# GD32F30x_XD register map
File version: 1.0
CPU: CM4 r2p1, little endian, MPU, FPU, 4 interrupt priority bits
Registers are 32-bit, read-write, reset 0x0 unless marked. A register's access mark holds for its fields unless they carry their own. Offsets are from the block's base; [hi:lo] are bit positions; {n}, {i} and the like mark numbered series.

## DAC — Digital-to-analog converter
Base 0x40007400
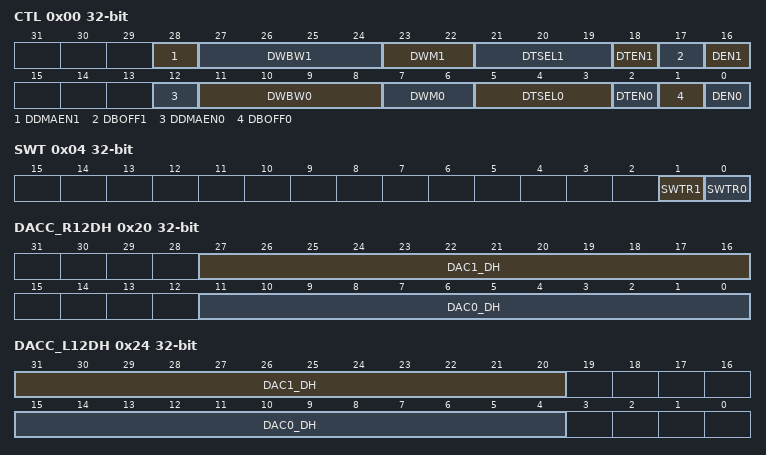
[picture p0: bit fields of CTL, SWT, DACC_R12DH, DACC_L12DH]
0x00 CTL — control register
  [28] DDMAEN1 — DAC1 DMA enable
  [27:24] DWBW1 — DAC1 noise wave bit width
  [23:22] DWM1 — DAC1 noise wave mode
  [21:19] DTSEL1 — DAC1 trigger selection
  [18] DTEN1 — DAC1 trigger enable
  [17] DBOFF1 — DAC1 output buffer turn off
  [16] DEN1 — DAC1 enable
  [12] DDMAEN0 — DAC0 DMA enable
  [11:8] DWBW0 — DAC0 noise wave bit width
  [7:6] DWM0 — DAC0 noise wave mode
  [5:3] DTSEL0 — DAC0 trigger selection
  [2] DTEN0 — DAC0 trigger enable
  [1] DBOFF0 — DAC0 output buffer turn off
  [0] DEN0 — DAC0 enable
0x04 SWT wo — software trigger register
  [1] SWTR1 — DAC1 software trigger
  [0] SWTR0 — DAC0 software trigger
0x08 OUT0_R12DH — DACx_OUT0 12-bit right-aligned data holding register
  [11:0] OUT0_DH — DACx_OUT0 12-bit right-aligned data
0x0C DOUT0_L12DH — DACx_OUT0 12-bit left-aligned data holding register
  [15:4] OUT0_DH — DACx_OUT0 12-bit left-aligned data
0x10 OUT0_R8DH — DACx_OUT0 8-bit right-aligned data holding register
  [7:0] OUT0_DH — DACx_OUT0 8-bit right-aligned data
0x14 OUT1_R12DH — DACx_OUT1 12-bit right-aligned data holding register
  [11:0] OUT1_DH — DACx_OUT1 12-bit right-aligned data
0x18 OUT1_L12DH — DACx_OUT1 12-bit left-aligned data holding register
  [15:4] OUT1_DH — DACx_OUT1 12-bit left-aligned data
0x1C OUT1_R8DH — DACx_OUT1 8-bit right-aligned data holding register (DAC_OUT1_R8DH)
  [7:0] DAC1_DH — DACx_OUT1 8-bit right-aligned data
0x20 DACC_R12DH — DAC concurrent mode 12-bit right-aligned data holding register
  [27:16] DAC1_DH — DAC1 12-bit right-aligned data
  [11:0] DAC0_DH — DAC0 12-bit right-aligned data
0x24 DACC_L12DH — DAC concurrent mode 12-bit left aligned data holding register
  [31:20] DAC1_DH — DAC1 12-bit left-aligned data
  [15:4] DAC0_DH — DAC0 12-bit left-aligned data
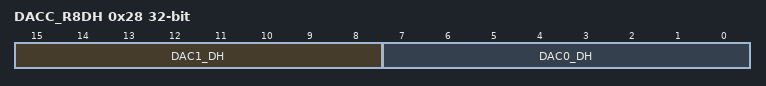
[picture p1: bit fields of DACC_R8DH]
0x28 DACC_R8DH — DAC concurrent mode 8-bit right aligned data holding register
  [15:8] DAC1_DH — DAC1 8-bit right-aligned data
  [7:0] DAC0_DH — DAC0 8-bit right-aligned data
0x2C DAC0_DO ro — DAC0 data output register
  [11:0] DAC0_DO — DAC0 data output
0x30 DAC1_DO ro — DAC1 data output register
  [11:0] DAC1_DO — DAC1 data output

## DBG — Debug support
Base 0xE0042000
0x00 ID ro — ID code register
  [31:0] ID_CODE — DBG ID code register
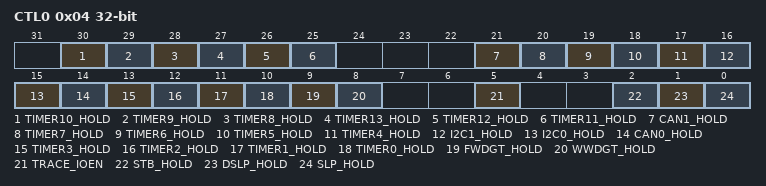
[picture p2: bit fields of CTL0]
0x04 CTL0 — Control register 0
  [30] TIMER10_HOLD — TIMER 10 hold bit
  [29] TIMER9_HOLD — TIMER 9 hold bit
  [28] TIMER8_HOLD — TIMER 8 hold bit
  [27] TIMER13_HOLD — TIMER 13 hold bit
  [26] TIMER12_HOLD — TIMER 12 hold bit
  [25] TIMER11_HOLD — TIMER 11 hold bit
  [21] CAN1_HOLD — CAN1 hold bit
  [20] TIMER7_HOLD — TIMER 7 hold bit
  [19] TIMER6_HOLD — TIMER 6 hold bit
  [18] TIMER5_HOLD — TIMER 5 hold bit
  [17] TIMER4_HOLD
  [16] I2C1_HOLD — I2C1 hold bit
  [15] I2C0_HOLD — I2C0 hold bit
  [14] CAN0_HOLD — CAN0 hold bit
  [13] TIMER3_HOLD — TIMER 23 hold bit
  [12] TIMER2_HOLD — TIMER 2 hold bit
  [11] TIMER1_HOLD — TIMER 1 hold bit
  [10] TIMER0_HOLD — TIMER 0 hold bit
  [9] FWDGT_HOLD — FWDGT hold bit
  [8] WWDGT_HOLD — WWDGT hold bit
  [5] TRACE_IOEN — Trace pin allocation enable
  [2] STB_HOLD — Standby mode hold register
  [1] DSLP_HOLD — Deep-sleep mode hold register
  [0] SLP_HOLD — Sleep mode hold register

## DMA0 — DMA controller
Base 0x40020000
Same registers: DMA1 0x40020400
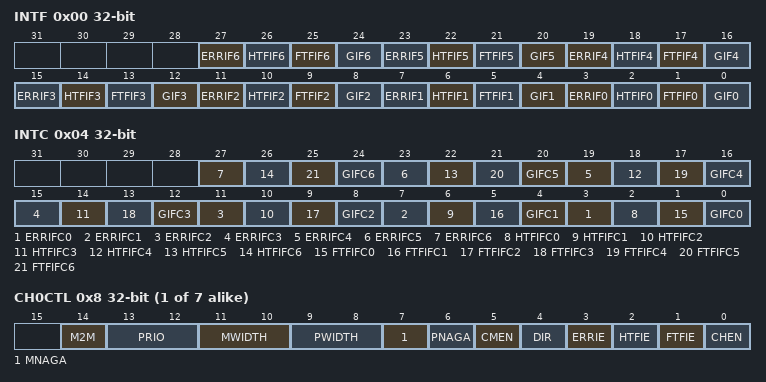
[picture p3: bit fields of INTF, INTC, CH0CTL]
0x00 INTF ro — Interrupt flag register
  [4n+3] ERRIF{n} (n=0..6) — Error flag of channel {n}
  [4n+2] HTFIF{n} (n=0..6) — Half transfer finish flag of channel {n}
  [4n+1] FTFIF{n} (n=0..6) — Full Transfer finish flag of channe {n}
  [4n] GIF{n} (n=0..6) — Global interrupt flag of channel {n}
0x04 INTC wo — Interrupt flag clear register
  [4n+3] ERRIFC{n} (n=0..6) — Clear bit for error flag of channel {n}
  [4n+2] HTFIFC{n} (n=0..6) — Clear bit for half transfer finish flag of channel {n}
  [4n+1] FTFIFC{n} (n=0..6) — Clear bit for full transfer finish flag of channel {n}
  [4n] GIFC{n} (n=0..6) — Clear global interrupt flag of channel {n}
{0x8+0x14*i} CH{i}CTL (i=0..6) — Channel {i} control register
  [14] M2M — Memory to Memory Mode
  [13:12] PRIO — Priority level
  [11:10] MWIDTH — Transfer data size of memory
  [9:8] PWIDTH — Transfer data size of peripheral
  [7] MNAGA — Next address generation algorithm of memory
  [6] PNAGA — Next address generation algorithm of peripheral
  [5] CMEN — Circular mode enable
  [4] DIR — Transfer direction
  [3] ERRIE — Enable bit for channel error interrupt
  [2] HTFIE — Enable bit for channel half transfer finish interrupt
  [1] FTFIE — Enable bit for channel full transfer finish interrupt
  [0] CHEN — Channel enable
{0xC+0x14*i} CH{i}CNT (i=0..6) — Channel {i} counter register
  [15:0] CNT — Transfer counter
{0x10+0x14*i} CH{i}PADDR (i=0..6) — Channel {i} peripheral base address register
  [31:0] PADDR — Peripheral base address
{0x14+0x14*i} CH{i}MADDR (i=0..6) — Channel {i} memory base address register
  [31:0] MADDR — Memory base address
